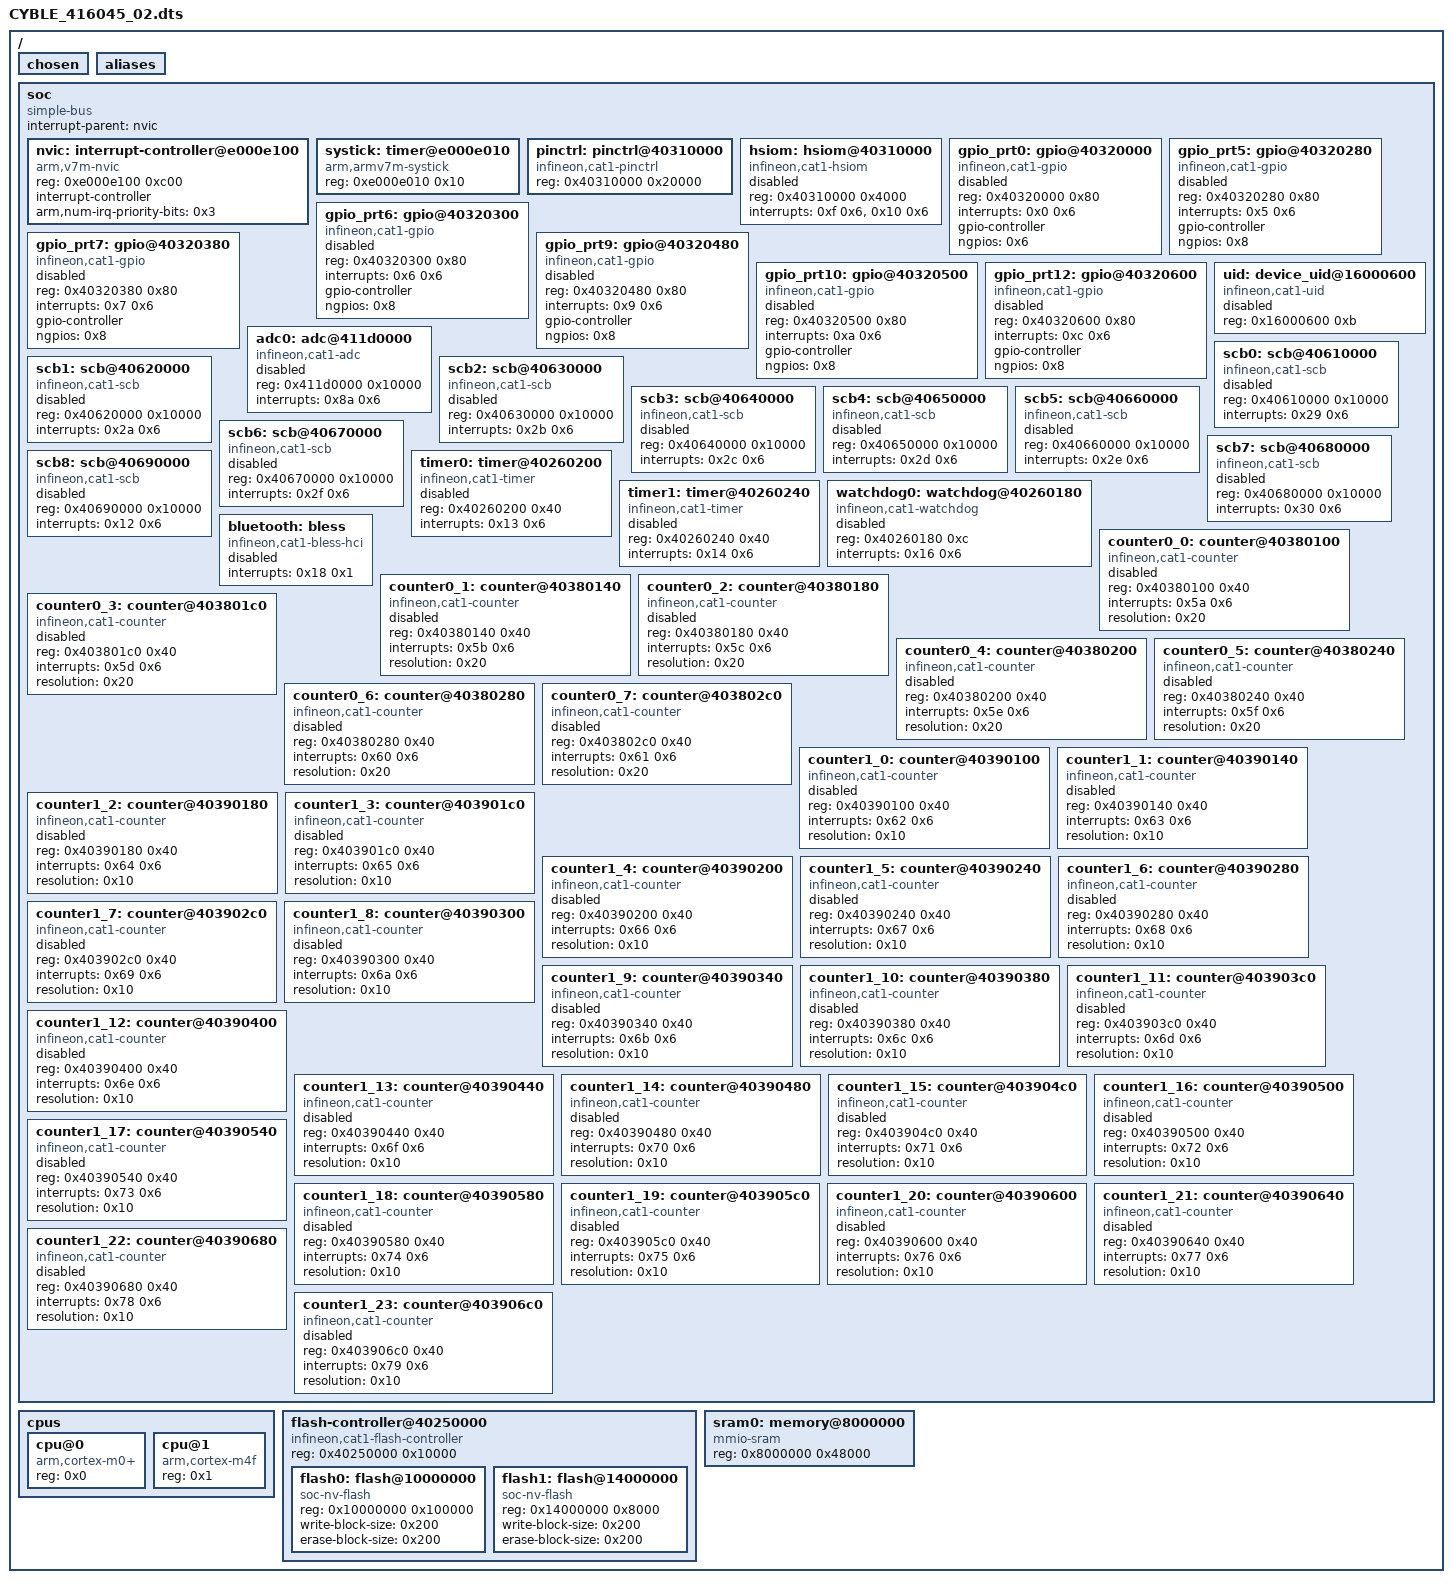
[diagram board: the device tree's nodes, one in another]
/dts-v1/;

/ {
	#address-cells = < 0x1 >;
	#size-cells = < 0x1 >;
	chosen {
	};
	aliases {
	};
	soc {
		#address-cells = < 0x1 >;
		#size-cells = < 0x1 >;
		compatible = "simple-bus";
		interrupt-parent = < &nvic >;
		ranges;
		nvic: interrupt-controller@e000e100 {
			#address-cells = < 0x1 >;
			compatible = "arm,v7m-nvic";
			reg = < 0xe000e100 0xc00 >;
			interrupt-controller;
			#interrupt-cells = < 0x2 >;
			arm,num-irq-priority-bits = < 0x3 >;
			phandle = < 0x1 >;
		};
		systick: timer@e000e010 {
			compatible = "arm,armv7m-systick";
			reg = < 0xe000e010 0x10 >;
		};
		pinctrl: pinctrl@40310000 {
			compatible = "infineon,cat1-pinctrl";
			reg = < 0x40310000 0x20000 >;
			#address-cells = < 0x1 >;
			#size-cells = < 0x0 >;
		};
		hsiom: hsiom@40310000 {
			compatible = "infineon,cat1-hsiom";
			reg = < 0x40310000 0x4000 >;
			interrupts = < 0xf 0x6 >, < 0x10 0x6 >;
			status = "disabled";
		};
		gpio_prt0: gpio@40320000 {
			compatible = "infineon,cat1-gpio";
			reg = < 0x40320000 0x80 >;
			interrupts = < 0x0 0x6 >;
			gpio-controller;
			ngpios = < 0x6 >;
			status = "disabled";
			#gpio-cells = < 0x2 >;
		};
		gpio_prt5: gpio@40320280 {
			compatible = "infineon,cat1-gpio";
			reg = < 0x40320280 0x80 >;
			interrupts = < 0x5 0x6 >;
			gpio-controller;
			ngpios = < 0x8 >;
			status = "disabled";
			#gpio-cells = < 0x2 >;
		};
		gpio_prt6: gpio@40320300 {
			compatible = "infineon,cat1-gpio";
			reg = < 0x40320300 0x80 >;
			interrupts = < 0x6 0x6 >;
			gpio-controller;
			ngpios = < 0x8 >;
			status = "disabled";
			#gpio-cells = < 0x2 >;
		};
		gpio_prt7: gpio@40320380 {
			compatible = "infineon,cat1-gpio";
			reg = < 0x40320380 0x80 >;
			interrupts = < 0x7 0x6 >;
			gpio-controller;
			ngpios = < 0x8 >;
			status = "disabled";
			#gpio-cells = < 0x2 >;
		};
		gpio_prt9: gpio@40320480 {
			compatible = "infineon,cat1-gpio";
			reg = < 0x40320480 0x80 >;
			interrupts = < 0x9 0x6 >;
			gpio-controller;
			ngpios = < 0x8 >;
			status = "disabled";
			#gpio-cells = < 0x2 >;
		};
		gpio_prt10: gpio@40320500 {
			compatible = "infineon,cat1-gpio";
			reg = < 0x40320500 0x80 >;
			interrupts = < 0xa 0x6 >;
			gpio-controller;
			ngpios = < 0x8 >;
			status = "disabled";
			#gpio-cells = < 0x2 >;
		};
		gpio_prt12: gpio@40320600 {
			compatible = "infineon,cat1-gpio";
			reg = < 0x40320600 0x80 >;
			interrupts = < 0xc 0x6 >;
			gpio-controller;
			ngpios = < 0x8 >;
			status = "disabled";
			#gpio-cells = < 0x2 >;
		};
		uid: device_uid@16000600 {
			compatible = "infineon,cat1-uid";
			reg = < 0x16000600 0xb >;
			status = "disabled";
		};
		adc0: adc@411d0000 {
			compatible = "infineon,cat1-adc";
			reg = < 0x411d0000 0x10000 >;
			interrupts = < 0x8a 0x6 >;
			status = "disabled";
			#io-channel-cells = < 0x1 >;
		};
		scb0: scb@40610000 {
			compatible = "infineon,cat1-scb";
			reg = < 0x40610000 0x10000 >;
			#address-cells = < 0x1 >;
			#size-cells = < 0x0 >;
			interrupts = < 0x29 0x6 >;
			status = "disabled";
		};
		scb1: scb@40620000 {
			compatible = "infineon,cat1-scb";
			reg = < 0x40620000 0x10000 >;
			#address-cells = < 0x1 >;
			#size-cells = < 0x0 >;
			interrupts = < 0x2a 0x6 >;
			status = "disabled";
		};
		scb2: scb@40630000 {
			compatible = "infineon,cat1-scb";
			reg = < 0x40630000 0x10000 >;
			#address-cells = < 0x1 >;
			#size-cells = < 0x0 >;
			interrupts = < 0x2b 0x6 >;
			status = "disabled";
		};
		scb3: scb@40640000 {
			compatible = "infineon,cat1-scb";
			reg = < 0x40640000 0x10000 >;
			#address-cells = < 0x1 >;
			#size-cells = < 0x0 >;
			interrupts = < 0x2c 0x6 >;
			status = "disabled";
		};
		scb4: scb@40650000 {
			compatible = "infineon,cat1-scb";
			reg = < 0x40650000 0x10000 >;
			#address-cells = < 0x1 >;
			#size-cells = < 0x0 >;
			interrupts = < 0x2d 0x6 >;
			status = "disabled";
		};
		scb5: scb@40660000 {
			compatible = "infineon,cat1-scb";
			reg = < 0x40660000 0x10000 >;
			#address-cells = < 0x1 >;
			#size-cells = < 0x0 >;
			interrupts = < 0x2e 0x6 >;
			status = "disabled";
		};
		scb6: scb@40670000 {
			compatible = "infineon,cat1-scb";
			reg = < 0x40670000 0x10000 >;
			#address-cells = < 0x1 >;
			#size-cells = < 0x0 >;
			interrupts = < 0x2f 0x6 >;
			status = "disabled";
		};
		scb7: scb@40680000 {
			compatible = "infineon,cat1-scb";
			reg = < 0x40680000 0x10000 >;
			#address-cells = < 0x1 >;
			#size-cells = < 0x0 >;
			interrupts = < 0x30 0x6 >;
			status = "disabled";
		};
		scb8: scb@40690000 {
			compatible = "infineon,cat1-scb";
			reg = < 0x40690000 0x10000 >;
			#address-cells = < 0x1 >;
			#size-cells = < 0x0 >;
			interrupts = < 0x12 0x6 >;
			status = "disabled";
		};
		timer0: timer@40260200 {
			compatible = "infineon,cat1-timer";
			reg = < 0x40260200 0x40 >;
			interrupts = < 0x13 0x6 >;
			status = "disabled";
		};
		timer1: timer@40260240 {
			compatible = "infineon,cat1-timer";
			reg = < 0x40260240 0x40 >;
			interrupts = < 0x14 0x6 >;
			status = "disabled";
		};
		watchdog0: watchdog@40260180 {
			compatible = "infineon,cat1-watchdog";
			reg = < 0x40260180 0xc >;
			interrupts = < 0x16 0x6 >;
			status = "disabled";
		};
		bluetooth: bless {
			compatible = "infineon,cat1-bless-hci";
			interrupts = < 0x18 0x1 >;
			status = "disabled";
		};
		counter0_0: counter@40380100 {
			compatible = "infineon,cat1-counter";
			reg = < 0x40380100 0x40 >;
			interrupts = < 0x5a 0x6 >;
			resolution = < 0x20 >;
			status = "disabled";
		};
		counter0_1: counter@40380140 {
			compatible = "infineon,cat1-counter";
			reg = < 0x40380140 0x40 >;
			interrupts = < 0x5b 0x6 >;
			resolution = < 0x20 >;
			status = "disabled";
		};
		counter0_2: counter@40380180 {
			compatible = "infineon,cat1-counter";
			reg = < 0x40380180 0x40 >;
			interrupts = < 0x5c 0x6 >;
			resolution = < 0x20 >;
			status = "disabled";
		};
		counter0_3: counter@403801c0 {
			compatible = "infineon,cat1-counter";
			reg = < 0x403801c0 0x40 >;
			interrupts = < 0x5d 0x6 >;
			resolution = < 0x20 >;
			status = "disabled";
		};
		counter0_4: counter@40380200 {
			compatible = "infineon,cat1-counter";
			reg = < 0x40380200 0x40 >;
			interrupts = < 0x5e 0x6 >;
			resolution = < 0x20 >;
			status = "disabled";
		};
		counter0_5: counter@40380240 {
			compatible = "infineon,cat1-counter";
			reg = < 0x40380240 0x40 >;
			interrupts = < 0x5f 0x6 >;
			resolution = < 0x20 >;
			status = "disabled";
		};
		counter0_6: counter@40380280 {
			compatible = "infineon,cat1-counter";
			reg = < 0x40380280 0x40 >;
			interrupts = < 0x60 0x6 >;
			resolution = < 0x20 >;
			status = "disabled";
		};
		counter0_7: counter@403802c0 {
			compatible = "infineon,cat1-counter";
			reg = < 0x403802c0 0x40 >;
			interrupts = < 0x61 0x6 >;
			resolution = < 0x20 >;
			status = "disabled";
		};
		counter1_0: counter@40390100 {
			compatible = "infineon,cat1-counter";
			reg = < 0x40390100 0x40 >;
			interrupts = < 0x62 0x6 >;
			resolution = < 0x10 >;
			status = "disabled";
		};
		counter1_1: counter@40390140 {
			compatible = "infineon,cat1-counter";
			reg = < 0x40390140 0x40 >;
			interrupts = < 0x63 0x6 >;
			resolution = < 0x10 >;
			status = "disabled";
		};
		counter1_2: counter@40390180 {
			compatible = "infineon,cat1-counter";
			reg = < 0x40390180 0x40 >;
			interrupts = < 0x64 0x6 >;
			resolution = < 0x10 >;
			status = "disabled";
		};
		counter1_3: counter@403901c0 {
			compatible = "infineon,cat1-counter";
			reg = < 0x403901c0 0x40 >;
			interrupts = < 0x65 0x6 >;
			resolution = < 0x10 >;
			status = "disabled";
		};
		counter1_4: counter@40390200 {
			compatible = "infineon,cat1-counter";
			reg = < 0x40390200 0x40 >;
			interrupts = < 0x66 0x6 >;
			resolution = < 0x10 >;
			status = "disabled";
		};
		counter1_5: counter@40390240 {
			compatible = "infineon,cat1-counter";
			reg = < 0x40390240 0x40 >;
			interrupts = < 0x67 0x6 >;
			resolution = < 0x10 >;
			status = "disabled";
		};
		counter1_6: counter@40390280 {
			compatible = "infineon,cat1-counter";
			reg = < 0x40390280 0x40 >;
			interrupts = < 0x68 0x6 >;
			resolution = < 0x10 >;
			status = "disabled";
		};
		counter1_7: counter@403902c0 {
			compatible = "infineon,cat1-counter";
			reg = < 0x403902c0 0x40 >;
			interrupts = < 0x69 0x6 >;
			resolution = < 0x10 >;
			status = "disabled";
		};
		counter1_8: counter@40390300 {
			compatible = "infineon,cat1-counter";
			reg = < 0x40390300 0x40 >;
			interrupts = < 0x6a 0x6 >;
			resolution = < 0x10 >;
			status = "disabled";
		};
		counter1_9: counter@40390340 {
			compatible = "infineon,cat1-counter";
			reg = < 0x40390340 0x40 >;
			interrupts = < 0x6b 0x6 >;
			resolution = < 0x10 >;
			status = "disabled";
		};
		counter1_10: counter@40390380 {
			compatible = "infineon,cat1-counter";
			reg = < 0x40390380 0x40 >;
			interrupts = < 0x6c 0x6 >;
			resolution = < 0x10 >;
			status = "disabled";
		};
		counter1_11: counter@403903c0 {
			compatible = "infineon,cat1-counter";
			reg = < 0x403903c0 0x40 >;
			interrupts = < 0x6d 0x6 >;
			resolution = < 0x10 >;
			status = "disabled";
		};
		counter1_12: counter@40390400 {
			compatible = "infineon,cat1-counter";
			reg = < 0x40390400 0x40 >;
			interrupts = < 0x6e 0x6 >;
			resolution = < 0x10 >;
			status = "disabled";
		};
		counter1_13: counter@40390440 {
			compatible = "infineon,cat1-counter";
			reg = < 0x40390440 0x40 >;
			interrupts = < 0x6f 0x6 >;
			resolution = < 0x10 >;
			status = "disabled";
		};
		counter1_14: counter@40390480 {
			compatible = "infineon,cat1-counter";
			reg = < 0x40390480 0x40 >;
			interrupts = < 0x70 0x6 >;
			resolution = < 0x10 >;
			status = "disabled";
		};
		counter1_15: counter@403904c0 {
			compatible = "infineon,cat1-counter";
			reg = < 0x403904c0 0x40 >;
			interrupts = < 0x71 0x6 >;
			resolution = < 0x10 >;
			status = "disabled";
		};
		counter1_16: counter@40390500 {
			compatible = "infineon,cat1-counter";
			reg = < 0x40390500 0x40 >;
			interrupts = < 0x72 0x6 >;
			resolution = < 0x10 >;
			status = "disabled";
		};
		counter1_17: counter@40390540 {
			compatible = "infineon,cat1-counter";
			reg = < 0x40390540 0x40 >;
			interrupts = < 0x73 0x6 >;
			resolution = < 0x10 >;
			status = "disabled";
		};
		counter1_18: counter@40390580 {
			compatible = "infineon,cat1-counter";
			reg = < 0x40390580 0x40 >;
			interrupts = < 0x74 0x6 >;
			resolution = < 0x10 >;
			status = "disabled";
		};
		counter1_19: counter@403905c0 {
			compatible = "infineon,cat1-counter";
			reg = < 0x403905c0 0x40 >;
			interrupts = < 0x75 0x6 >;
			resolution = < 0x10 >;
			status = "disabled";
		};
		counter1_20: counter@40390600 {
			compatible = "infineon,cat1-counter";
			reg = < 0x40390600 0x40 >;
			interrupts = < 0x76 0x6 >;
			resolution = < 0x10 >;
			status = "disabled";
		};
		counter1_21: counter@40390640 {
			compatible = "infineon,cat1-counter";
			reg = < 0x40390640 0x40 >;
			interrupts = < 0x77 0x6 >;
			resolution = < 0x10 >;
			status = "disabled";
		};
		counter1_22: counter@40390680 {
			compatible = "infineon,cat1-counter";
			reg = < 0x40390680 0x40 >;
			interrupts = < 0x78 0x6 >;
			resolution = < 0x10 >;
			status = "disabled";
		};
		counter1_23: counter@403906c0 {
			compatible = "infineon,cat1-counter";
			reg = < 0x403906c0 0x40 >;
			interrupts = < 0x79 0x6 >;
			resolution = < 0x10 >;
			status = "disabled";
		};
	};
	cpus {
		#address-cells = < 0x1 >;
		#size-cells = < 0x0 >;
		cpu@0 {
			device_type = "cpu";
			compatible = "arm,cortex-m0+";
			reg = < 0x0 >;
		};
		cpu@1 {
			device_type = "cpu";
			compatible = "arm,cortex-m4f";
			reg = < 0x1 >;
		};
	};
	flash-controller@40250000 {
		compatible = "infineon,cat1-flash-controller";
		reg = < 0x40250000 0x10000 >;
		#address-cells = < 0x1 >;
		#size-cells = < 0x1 >;
		flash0: flash@10000000 {
			compatible = "soc-nv-flash";
			reg = < 0x10000000 0x100000 >;
			write-block-size = < 0x200 >;
			erase-block-size = < 0x200 >;
		};
		flash1: flash@14000000 {
			compatible = "soc-nv-flash";
			reg = < 0x14000000 0x8000 >;
			write-block-size = < 0x200 >;
			erase-block-size = < 0x200 >;
		};
	};
	sram0: memory@8000000 {
		compatible = "mmio-sram";
		reg = < 0x8000000 0x48000 >;
	};
};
